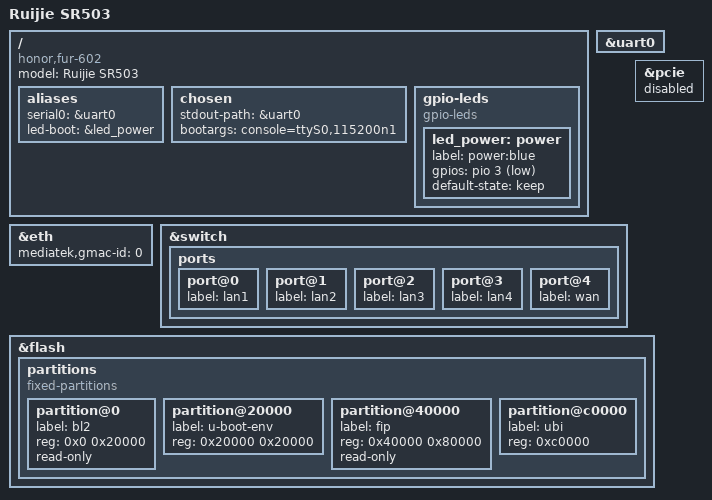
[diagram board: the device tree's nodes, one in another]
// Honor FUR‑602 MT7981B
/dts-v1/;
#include <mt7981.dtsi>


/ {
	compatible = "honor,fur‑602", "mediatek,mt7981";
	model = "Ruijie SR503";

	aliases {
		serial0 = &uart0;
		led‑boot = &led_power;
	};

	chosen {
		stdout‑path = &uart0;
		bootargs = "console=ttyS0,115200n1";
	};

	gpio‑leds {
		compatible = "gpio‑leds";

		led_power: power {
			label = "power:blue";
			gpios = <&pio 3 GPIO_ACTIVE_LOW>;
			default‑state = "keep";
		};
	};
};

&uart0 {
	status = "okay";
};

&eth {
	status = "okay";
	mediatek,gmac‑id = <0>;
};

&switch {
	ports {
		port@0 {
			status = "okay";
			label = "lan1";
		};
		port@1 {
			status = "okay";
			label = "lan2";
		};
		port@2 {
			status = "okay";
			label = "lan3";
		};
		port@3 {
			status = "okay";
			label = "lan4";
		};
		port@4 {
			status = "okay";
			label = "wan";
		};
	};
};

&pcie {
	status = "disabled";
};

&flash {
	status = "okay";

	partitions {
		compatible = "fixed‑partitions";

		partition@0 {
			label = "bl2";
			reg = <0x0 0x20000>;
			read‑only;
		};
		partition@20000 {
			label = "u‑boot‑env";
			reg = <0x20000 0x20000>;
		};
		partition@40000 {
			label = "fip";
			reg = <0x40000 0x80000>;
			read‑only;
		};
		partition@c0000 {
			label = "ubi";
			reg = <0xc0000>;
		};
	};
};
